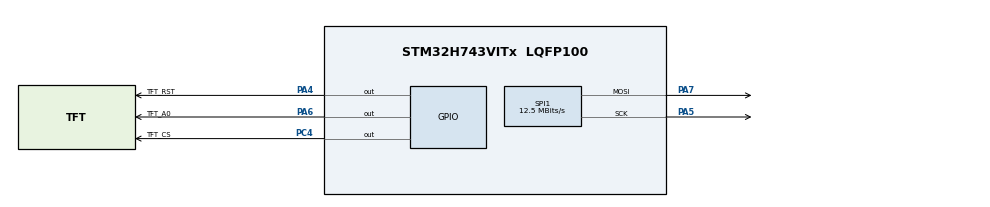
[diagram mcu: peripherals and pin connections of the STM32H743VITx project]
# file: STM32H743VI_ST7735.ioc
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Mcu.Family=STM32H7
Mcu.Name=STM32H743VITx
Mcu.Package=LQFP100
NVIC.PriorityGroup=NVIC_PRIORITYGROUP_4
PA4.GPIO_Label=TFT_RST
PA4.GPIO_PuPd=GPIO_NOPULL
PA4.GPIO_Speed=GPIO_SPEED_FREQ_HIGH
PA4.Signal=GPIO_Output
PA5.Mode=TX_Only_Simplex_Unidirect_Master
PA5.Signal=SPI1_SCK
PA6.GPIO_Label=TFT_A0
PA6.GPIO_PuPd=GPIO_NOPULL
PA6.GPIO_Speed=GPIO_SPEED_FREQ_HIGH
PA6.Signal=GPIO_Output
PA7.Mode=TX_Only_Simplex_Unidirect_Master
PA7.Signal=SPI1_MOSI
PC4.GPIO_Label=TFT_CS
PC4.GPIO_PuPd=GPIO_NOPULL
PC4.GPIO_Speed=GPIO_SPEED_FREQ_HIGH
PC4.Signal=GPIO_Output
ProjectManager.HeapSize=0x200
ProjectManager.StackSize=0x400
ProjectManager.TargetToolchain=STM32CubeIDE
RCC.ADCFreq_Value=37500000
RCC.APB1Freq_Value=100000000
RCC.APB2Freq_Value=100000000
RCC.APB3Freq_Value=100000000
RCC.APB4Freq_Value=100000000
RCC.CortexFreq_Value=100000000
RCC.DIVM1=4
RCC.DIVM2=4
RCC.DIVN1=12
RCC.DIVN2=9
RCC.DIVP2=4
RCC.HCLKFreq_Value=100000000
RCC.PLL2FRACN=3072
RCC.PLL3FRACN=0
RCC.PLLFRACN=4096
RCC.SYSCLKFreq_VALUE=100000000
RCC.SYSCLKSource=RCC_SYSCLKSOURCE_PLLCLK
RCC.USBFreq_Value=100000000
SPI1.BaudRatePrescaler=SPI_BAUDRATEPRESCALER_8
SPI1.CalculateBaudRate=12.5 MBits/s
SPI1.DataSize=SPI_DATASIZE_8BIT
SPI1.Direction=SPI_DIRECTION_2LINES_TXONLY
SPI1.FirstBit=SPI_FIRSTBIT_MSB
SPI1.Mode=SPI_MODE_MASTER
SPI1.VirtualType=VM_MASTER
board=custom

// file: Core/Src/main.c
/* USER CODE BEGIN Header */
/**
  ******************************************************************************
  * @file           : main.c
  * @brief          : Main program body
  ******************************************************************************
  * @attention
  *
  * <h2><center>&copy; Copyright (c) 2021 STMicroelectronics.
  * All rights reserved.</center></h2>
  *
  * This software component is licensed by ST under BSD 3-Clause license,
  * the "License"; You may not use this file except in compliance with the
  * License. You may obtain a copy of the License at:
  *                        opensource.org/licenses/BSD-3-Clause
  *
  ******************************************************************************
  */
/* USER CODE END Header */
#include "main.h"

SPI_HandleTypeDef hspi1;

void SystemClock_Config(void);
static void MX_GPIO_Init(void);
static void MX_SPI1_Init(void);

int main(void)
{

  /* MCU Configuration--------------------------------------------------------*/

  /* Reset of all peripherals, Initializes the Flash interface and the Systick. */
  HAL_Init();

  /* Configure the system clock */
  SystemClock_Config();

  /* Initialize all configured peripherals */
  MX_GPIO_Init();
  MX_SPI1_Init();
  /* USER CODE BEGIN 2 */
  jump_to_cpp();
  /* USER CODE END 2 */

  /* Infinite loop */
  while (1)
  {

  }
}

void SystemClock_Config(void)
{
  RCC_OscInitTypeDef RCC_OscInitStruct = {0};
  RCC_ClkInitTypeDef RCC_ClkInitStruct = {0};

  /** Supply configuration update enable
  */
  HAL_PWREx_ConfigSupply(PWR_LDO_SUPPLY);
  /** Configure the main internal regulator output voltage
  */
  __HAL_PWR_VOLTAGESCALING_CONFIG(PWR_REGULATOR_VOLTAGE_SCALE3);

  while(!__HAL_PWR_GET_FLAG(PWR_FLAG_VOSRDY)) {}
  /** Initializes the RCC Oscillators according to the specified parameters
  * in the RCC_OscInitTypeDef structure.
  */
  RCC_OscInitStruct.OscillatorType = RCC_OSCILLATORTYPE_HSI;
  RCC_OscInitStruct.HSIState = RCC_HSI_DIV1;
  RCC_OscInitStruct.HSICalibrationValue = RCC_HSICALIBRATION_DEFAULT;
  RCC_OscInitStruct.PLL.PLLState = RCC_PLL_ON;
  RCC_OscInitStruct.PLL.PLLSource = RCC_PLLSOURCE_HSI;
  RCC_OscInitStruct.PLL.PLLM = 4;
  RCC_OscInitStruct.PLL.PLLN = 12;
  RCC_OscInitStruct.PLL.PLLP = 2;
  RCC_OscInitStruct.PLL.PLLQ = 2;
  RCC_OscInitStruct.PLL.PLLR = 2;
  RCC_OscInitStruct.PLL.PLLRGE = RCC_PLL1VCIRANGE_3;
  RCC_OscInitStruct.PLL.PLLVCOSEL = RCC_PLL1VCOWIDE;
  RCC_OscInitStruct.PLL.PLLFRACN = 4096;
  if (HAL_RCC_OscConfig(&RCC_OscInitStruct) != HAL_OK)
  {
    Error_Handler();
  }
  /** Initializes the CPU, AHB and APB buses clocks
  */
  RCC_ClkInitStruct.ClockType = RCC_CLOCKTYPE_HCLK|RCC_CLOCKTYPE_SYSCLK
                              |RCC_CLOCKTYPE_PCLK1|RCC_CLOCKTYPE_PCLK2
                              |RCC_CLOCKTYPE_D3PCLK1|RCC_CLOCKTYPE_D1PCLK1;
  RCC_ClkInitStruct.SYSCLKSource = RCC_SYSCLKSOURCE_PLLCLK;
  RCC_ClkInitStruct.SYSCLKDivider = RCC_SYSCLK_DIV1;
  RCC_ClkInitStruct.AHBCLKDivider = RCC_HCLK_DIV1;
  RCC_ClkInitStruct.APB3CLKDivider = RCC_APB3_DIV1;
  RCC_ClkInitStruct.APB1CLKDivider = RCC_APB1_DIV1;
  RCC_ClkInitStruct.APB2CLKDivider = RCC_APB2_DIV1;
  RCC_ClkInitStruct.APB4CLKDivider = RCC_APB4_DIV1;

  if (HAL_RCC_ClockConfig(&RCC_ClkInitStruct, FLASH_LATENCY_2) != HAL_OK)
  {
    Error_Handler();
  }
}

static void MX_SPI1_Init(void)
{

  /* SPI1 parameter configuration*/
  hspi1.Instance = SPI1;
  hspi1.Init.Mode = SPI_MODE_MASTER;
  hspi1.Init.Direction = SPI_DIRECTION_2LINES_TXONLY;
  hspi1.Init.DataSize = SPI_DATASIZE_8BIT;
  hspi1.Init.CLKPolarity = SPI_POLARITY_LOW;
  hspi1.Init.CLKPhase = SPI_PHASE_1EDGE;
  hspi1.Init.NSS = SPI_NSS_SOFT;
  hspi1.Init.BaudRatePrescaler = SPI_BAUDRATEPRESCALER_8;
  hspi1.Init.FirstBit = SPI_FIRSTBIT_MSB;
  hspi1.Init.TIMode = SPI_TIMODE_DISABLE;
  hspi1.Init.CRCCalculation = SPI_CRCCALCULATION_DISABLE;
  hspi1.Init.CRCPolynomial = 0x0;
  hspi1.Init.NSSPMode = SPI_NSS_PULSE_ENABLE;
  hspi1.Init.NSSPolarity = SPI_NSS_POLARITY_LOW;
  hspi1.Init.FifoThreshold = SPI_FIFO_THRESHOLD_01DATA;
  hspi1.Init.TxCRCInitializationPattern = SPI_CRC_INITIALIZATION_ALL_ZERO_PATTERN;
  hspi1.Init.RxCRCInitializationPattern = SPI_CRC_INITIALIZATION_ALL_ZERO_PATTERN;
  hspi1.Init.MasterSSIdleness = SPI_MASTER_SS_IDLENESS_00CYCLE;
  hspi1.Init.MasterInterDataIdleness = SPI_MASTER_INTERDATA_IDLENESS_00CYCLE;
  hspi1.Init.MasterReceiverAutoSusp = SPI_MASTER_RX_AUTOSUSP_DISABLE;
  hspi1.Init.MasterKeepIOState = SPI_MASTER_KEEP_IO_STATE_DISABLE;
  hspi1.Init.IOSwap = SPI_IO_SWAP_DISABLE;
  if (HAL_SPI_Init(&hspi1) != HAL_OK)
  {
    Error_Handler();
  }

}

static void MX_GPIO_Init(void)
{
  GPIO_InitTypeDef GPIO_InitStruct = {0};

  /* GPIO Ports Clock Enable */
  __HAL_RCC_GPIOA_CLK_ENABLE();
  __HAL_RCC_GPIOC_CLK_ENABLE();

  /*Configure GPIO pin Output Level */
  HAL_GPIO_WritePin(GPIOA, TFT_RST_Pin|TFT_A0_Pin, GPIO_PIN_RESET);

  /*Configure GPIO pin Output Level */
  HAL_GPIO_WritePin(TFT_CS_GPIO_Port, TFT_CS_Pin, GPIO_PIN_RESET);

  /*Configure GPIO pins : TFT_RST_Pin TFT_A0_Pin */
  GPIO_InitStruct.Pin = TFT_RST_Pin|TFT_A0_Pin;
  GPIO_InitStruct.Mode = GPIO_MODE_OUTPUT_PP;
  GPIO_InitStruct.Pull = GPIO_NOPULL;
  GPIO_InitStruct.Speed = GPIO_SPEED_FREQ_HIGH;
  HAL_GPIO_Init(GPIOA, &GPIO_InitStruct);

  /*Configure GPIO pin : TFT_CS_Pin */
  GPIO_InitStruct.Pin = TFT_CS_Pin;
  GPIO_InitStruct.Mode = GPIO_MODE_OUTPUT_PP;
  GPIO_InitStruct.Pull = GPIO_NOPULL;
  GPIO_InitStruct.Speed = GPIO_SPEED_FREQ_HIGH;
  HAL_GPIO_Init(TFT_CS_GPIO_Port, &GPIO_InitStruct);

}

void Error_Handler(void)
{
  __disable_irq();
  while (1)
  {
  }
}

/************************ (C) COPYRIGHT STMicroelectronics *****END OF FILE****/
